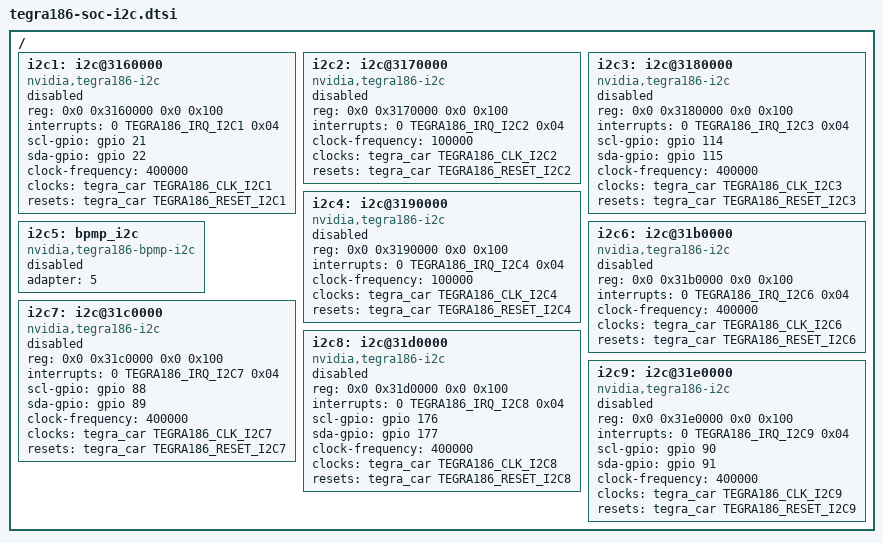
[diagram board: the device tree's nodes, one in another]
/*
 * Copyright (c) 2015, NVIDIA CORPORATION.  All rights reserved.
 *
 * This program is free software; you can redistribute it and/or modify
 * it under the terms of the GNU General Public License as published by
 * the Free Software Foundation; version 2 of the License.
 *
 * This program is distributed in the hope that it will be useful, but WITHOUT
 * ANY WARRANTY; without even the implied warranty of MERCHANTABILITY or
 * FITNESS FOR A PARTICULAR PURPOSE.  See the GNU General Public License for
 * more details.
 *
 * You should have received a copy of the GNU General Public License along
 * with this program; if not, write to the Free Software Foundation, Inc.,
 * 51 Franklin Street, Fifth Floor, Boston, MA  02110-1301, USA.
 *
 */

/ {
	i2c1: i2c@3160000 {
		#address-cells = <1>;
		#size-cells = <0>;
		compatible = "nvidia,tegra186-i2c";
		reg = <0x0 0x3160000 0x0 0x100>;
		interrupts = <0 TEGRA186_IRQ_I2C1 0x04>;
		scl-gpio = <&gpio 21 0>;
		sda-gpio = <&gpio 22 0>;
		status = "disabled";
		clock-frequency = <400000>;
		clocks = <&tegra_car TEGRA186_CLK_I2C1>;
		clock-names = "div-clk";
		resets = <&tegra_car TEGRA186_RESET_I2C1>;
		reset-names = "i2c";
	};

	i2c2: i2c@3170000 {
		#address-cells = <1>;
		#size-cells = <0>;
		compatible = "nvidia,tegra186-i2c";
		reg = <0x0 0x3170000 0x0 0x100>;
		interrupts = <0 TEGRA186_IRQ_I2C2 0x04>;
		status = "disabled";
		clock-frequency = <100000>;
		clocks = <&tegra_car TEGRA186_CLK_I2C2>;
		clock-names = "div-clk";
		resets = <&tegra_car TEGRA186_RESET_I2C2>;
		reset-names = "i2c";
	};

	i2c3: i2c@3180000 {
		#address-cells = <1>;
		#size-cells = <0>;
		compatible = "nvidia,tegra186-i2c";
		reg = <0x0 0x3180000 0x0 0x100>;
		interrupts = <0 TEGRA186_IRQ_I2C3 0x04>;
		scl-gpio = <&gpio 114 0>;
		sda-gpio = <&gpio 115 0>;
		status = "disabled";
		clock-frequency = <400000>;
		clocks = <&tegra_car TEGRA186_CLK_I2C3>;
		clock-names = "div-clk";
		resets = <&tegra_car TEGRA186_RESET_I2C3>;
		reset-names = "i2c";
	};

	i2c4: i2c@3190000 {
		#address-cells = <1>;
		#size-cells = <0>;
		compatible = "nvidia,tegra186-i2c";
		reg = <0x0 0x3190000 0x0 0x100>;
		interrupts = <0 TEGRA186_IRQ_I2C4 0x04>;
		status = "disabled";
		clock-frequency = <100000>;
		clocks = <&tegra_car TEGRA186_CLK_I2C4>;
		clock-names = "div-clk";
		resets = <&tegra_car TEGRA186_RESET_I2C4>;
		reset-names = "i2c";
	};

	i2c5: bpmp_i2c {
		#address-cells = <1>;
		#size-cells = <0>;
		compatible = "nvidia,tegra186-bpmp-i2c";
		status = "disabled";
		adapter = <5>;
	};

	i2c6: i2c@31b0000 {
		#address-cells = <1>;
		#size-cells = <0>;
		compatible = "nvidia,tegra186-i2c";
		reg = <0x0 0x31b0000 0x0 0x100>;
		interrupts = <0 TEGRA186_IRQ_I2C6 0x04>;
		status = "disabled";
		clock-frequency = <400000>;
		clocks = <&tegra_car TEGRA186_CLK_I2C6>;
		clock-names = "div-clk";
		resets = <&tegra_car TEGRA186_RESET_I2C6>;
		reset-names = "i2c";
	};

	i2c7: i2c@31c0000 {
		#address-cells = <1>;
		#size-cells = <0>;
		compatible = "nvidia,tegra186-i2c";
		reg = <0x0 0x31c0000 0x0 0x100>;
		interrupts = <0 TEGRA186_IRQ_I2C7 0x04>;
		scl-gpio = <&gpio 88 0>;
		sda-gpio = <&gpio 89 0>;
		status = "disabled";
		clock-frequency = <400000>;
		clocks = <&tegra_car TEGRA186_CLK_I2C7>;
		clock-names = "div-clk";
		resets = <&tegra_car TEGRA186_RESET_I2C7>;
		reset-names = "i2c";
	};

	i2c8: i2c@31d0000 {
		#address-cells = <1>;
		#size-cells = <0>;
		compatible = "nvidia,tegra186-i2c";
		reg = <0x0 0x31d0000 0x0 0x100>;
		interrupts = <0 TEGRA186_IRQ_I2C8 0x04>;
		scl-gpio = <&gpio 176 0>;
		sda-gpio = <&gpio 177 0>;
		status = "disabled";
		clock-frequency = <400000>;
		clocks = <&tegra_car TEGRA186_CLK_I2C8>;
		clock-names = "div-clk";
		resets = <&tegra_car TEGRA186_RESET_I2C8>;
		reset-names = "i2c";
	};

	i2c9: i2c@31e0000 {
		#address-cells = <1>;
		#size-cells = <0>;
		compatible = "nvidia,tegra186-i2c";
		reg = <0x0 0x31e0000 0x0 0x100>;
		interrupts = <0 TEGRA186_IRQ_I2C9 0x04>;
		scl-gpio = <&gpio 90 0>;
		sda-gpio = <&gpio 91 0>;
		status = "disabled";
		clock-frequency = <400000>;
		clocks = <&tegra_car TEGRA186_CLK_I2C9>;
		clock-names = "div-clk";
		resets = <&tegra_car TEGRA186_RESET_I2C9>;
		reset-names = "i2c";
	};
};
